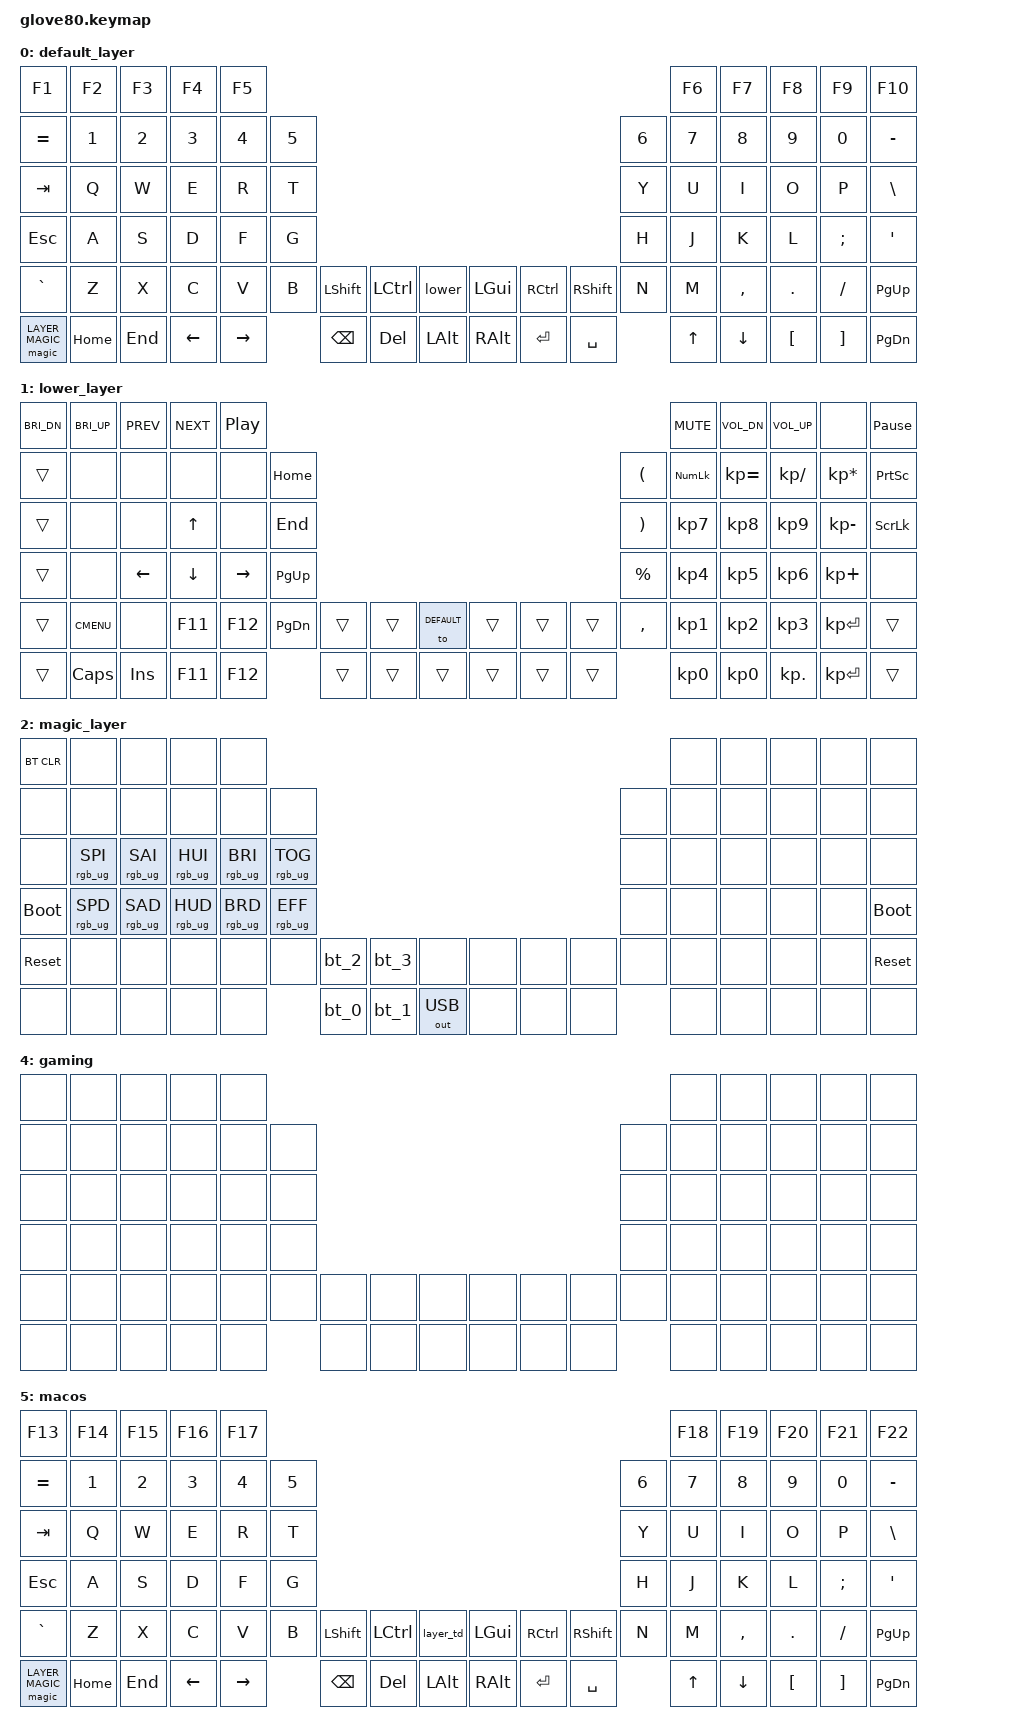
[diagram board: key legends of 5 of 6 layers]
/*
 * Copyright (c) 2020 The ZMK Contributors
 *
 * SPDX-License-Identifier: MIT
 */

#include <behaviors.dtsi>
#include <dt-bindings/zmk/keys.h>
#include <dt-bindings/zmk/bt.h>
#include <dt-bindings/zmk/ext_power.h>
#include <dt-bindings/zmk/outputs.h>
#include <dt-bindings/zmk/rgb.h>
#include "glove80_keypositions.h"

// layers

#define LAYER_DEFAULT      0
#define LAYER_LOWER        1
#define LAYER_MAGIC        2
#define LAYER_FUNCTION     3
#define LAYER_GAMING       4
#define LAYER_MACOS        5

/ {
    behaviors {
        // For the "layer" key, it'd nice to be able to use it as either a shift or a toggle.
        // Configure it as a tap dance, so the first tap (or hold) is a &mo and the second tap is a &to
        // layer_td: tap_dance_0 {
            // compatible = "zmk,behavior-tap-dance";
            // #binding-cells = <0>;
            // tapping-term-ms = <200>;
            // bindings = <&mo LOWER>, <&to LOWER>;
        // };
        vbatt: vbatt {
            compatible = "zmk,battery-nrf-vddh";
        };

        skq: sticky_key_quick_release {
            compatible = "zmk,behavior-sticky-key";
            #binding-cells = <1>;
            bindings = <&kp>;
            release-after-ms = <1000>;
            quick-release;
            ignore-modifiers;
        };

        lower: lower {
            compatible = "zmk,behavior-tap-dance";
            label = "LAYER_TAP_DANCE";
            #binding-cells = <0>;
            tapping-term-ms = <200>;
            bindings = <&mo LAYER_LOWER>, <&to LAYER_LOWER>;
        };

    };

    macros {
        rgb_ug_status_macro: rgb_ug_status_macro {
            label = "RGB_UG_STATUS";
            compatible = "zmk,behavior-macro";
            #binding-cells = <0>;
            bindings
                = <&rgb_ug RGB_STATUS>;
        };
    };
};

/ {
    behaviors {
        magic: magic {
            compatible = "zmk,behavior-hold-tap";
            label = "MAGIC_HOLD_TAP";
            #binding-cells = <1>;
            flavor = "tap-preferred";
            tapping-term-ms = <200>;
            bindings = <&mo>, <&rgb_ug_status_macro>;
        };
    }

};


/ {
#ifdef BT_DISC_CMD
    behaviors {
        bt_0: bt_0 {
            compatible = "zmk,behavior-tap-dance";
            label = "BT_0";
            #binding-cells = <0>;
            tapping-term-ms = <200>;
            bindings = <&bt_select_0>, <&bt BT_DISC 0>;
        };
        bt_1: bt_1 {
            compatible = "zmk,behavior-tap-dance";
            label = "BT_1";
            #binding-cells = <0>;
            tapping-term-ms = <200>;
            bindings = <&bt_select_1>, <&bt BT_DISC 1>;
        };
        bt_2: bt_2 {
            compatible = "zmk,behavior-tap-dance";
            label = "BT_2";
            #binding-cells = <0>;
            tapping-term-ms = <200>;
            bindings = <&bt_select_2>, <&bt BT_DISC 2>;
        };
        bt_3: bt_3 {
            compatible = "zmk,behavior-tap-dance";
            label = "BT_3";
            #binding-cells = <0>;
            tapping-term-ms = <200>;
            bindings = <&bt_select_3>, <&bt BT_DISC 3>;
        };
    };
    macros {
        bt_select_0: bt_select_0 {
            label = "BT_SELECT_0";
            compatible = "zmk,behavior-macro";
            #binding-cells = <0>;
            bindings
                = <&out OUT_BLE>,
                  <&bt BT_SEL 0>;
        };
        bt_select_1: bt_select_1 {
            label = "BT_SELECT_1";
            compatible = "zmk,behavior-macro";
            #binding-cells = <0>;
            bindings
                = <&out OUT_BLE>,
                  <&bt BT_SEL 1>;
        };
        bt_select_2: bt_select_2 {
            label = "BT_SELECT_2";
            compatible = "zmk,behavior-macro";
            #binding-cells = <0>;
            bindings
                = <&out OUT_BLE>,
                  <&bt BT_SEL 2>;
        };
        bt_select_3: bt_select_3 {
            label = "BT_SELECT_3";
            compatible = "zmk,behavior-macro";
            #binding-cells = <0>;
            bindings
                = <&out OUT_BLE>,
                  <&bt BT_SEL 3>;
        };
    };
#else
    macros {
        bt_0: bt_profile_macro_0 {
            compatible = "zmk,behavior-macro";
            #binding-cells = <0>;
            bindings
                = <&out OUT_BLE>,
                  <&bt BT_SEL 0>;
        };

        bt_1: bt_profile_macro_1 {
            compatible = "zmk,behavior-macro";
            #binding-cells = <0>;
            bindings
                = <&out OUT_BLE>,
                  <&bt BT_SEL 1>;
        };

        bt_2: bt_profile_macro_2 {
            compatible = "zmk,behavior-macro";
            #binding-cells = <0>;
            bindings
                = <&out OUT_BLE>,
                  <&bt BT_SEL 2>;
        };

        bt_3: bt_profile_macro_3 {
            compatible = "zmk,behavior-macro";
            #binding-cells = <0>;
            bindings
                = <&out OUT_BLE>,
                  <&bt BT_SEL 3>;
        };
    };
    #endif

    keymap {
        compatible = "zmk,keymap";

        default_layer {

            bindings = <
//    ┌──────────────────────┬──────┬─────┬──────┬──────┐                                                   ┌────┬──────┬────┬────┬──────┐
//    │          f1          │  f2  │ f3  │  f4  │  f5  │                                                   │ f6 │  f7  │ f8 │ f9 │ f10  │
//    ├──────────────────────┼──────┼─────┼──────┼──────┼───┐                                           ┌───┼────┼──────┼────┼────┼──────┤
//    │          =           │  1   │  2  │  3   │  4   │ 5 │                                           │ 6 │ 7  │  8   │ 9  │ 0  │  -   │
//    ├──────────────────────┼──────┼─────┼──────┼──────┼───┤                                           ├───┼────┼──────┼────┼────┼──────┤
//    │         tab          │  Q   │  W  │  E   │  R   │ T │                                           │ Y │ U  │  I   │ O  │ P  │  \   │
//    ├──────────────────────┼──────┼─────┼──────┼──────┼───┤                                           ├───┼────┼──────┼────┼────┼──────┤
//    │         esc          │  A   │  S  │  D   │  F   │ G │                                           │ H │ J  │  K   │ L  │ ;  │  '   │
//    ├──────────────────────┼──────┼─────┼──────┼──────┼───┼──────┬──────┬────────┬──────┬──────┬──────┼───┼────┼──────┼────┼────┼──────┤
//    │          `           │  Z   │  X  │  C   │  V   │ B │ lsft │ lctl │ &lower │ lgui │ rctl │ rsft │ N │ M  │  ,   │ .  │ /  │ pgup │
//    ├──────────────────────┼──────┼─────┼──────┼──────┼───┼──────┼──────┼────────┼──────┼──────┼──────┼───┼────┼──────┼────┼────┼──────┤
//    │ &magic laltYER_MAGIC │ home │ end │ left │ rght │   │ bspc │ del  │  lalt  │ ralt │ ent  │ spc  │   │ up │ down │ [  │ ]  │ pgdn │
//    └──────────────────────┴──────┴─────┴──────┴──────┘   └──────┴──────┴────────┴──────┴──────┴──────┘   └────┴──────┴────┴────┴──────┘
  &kp F1               &kp F2     &kp F3    &kp F4     &kp F5                                                                                              &kp F6   &kp F7      &kp F8     &kp F9     &kp F10
  &kp EQUAL            &kp N1     &kp N2    &kp N3     &kp N4      &kp N5                                                                         &kp N6   &kp N7   &kp N8      &kp N9     &kp N0     &kp MINUS
  &kp TAB              &kp Q      &kp W     &kp E      &kp R       &kp T                                                                          &kp Y    &kp U    &kp I       &kp O      &kp P      &kp BSLH
  &kp ESC              &kp A      &kp S     &kp D      &kp F       &kp G                                                                          &kp H    &kp J    &kp K       &kp L      &kp SEMI   &kp SQT
  &kp GRAVE            &kp Z      &kp X     &kp C      &kp V       &kp B    &kp LSHFT   &kp LCTRL   &lower     &kp LGUI   &kp RCTRL   &kp RSHFT   &kp N    &kp M    &kp COMMA   &kp DOT    &kp FSLH   &kp PG_UP
  &magic LAYER_MAGIC   &kp HOME   &kp END   &kp LEFT   &kp RIGHT            &kp BSPC    &kp DEL     &kp LALT   &kp RALT   &kp RET     &kp SPACE            &kp UP   &kp DOWN    &kp LBKT   &kp RBKT   &kp PG_DN
            >;
        };

        lower_layer {
            bindings = <
//    ┌──────┬──────┬──────┬──────┬──────┐                                                    ┌──────┬──────┬──────┬──────┬──────┐
//    │ bri- │ bri+ │ prev │ next │ play │                                                    │ mute │ vold │ volu │      │ paus │
//    ├──────┼──────┼──────┼──────┼──────┼──────┐                                         ┌───┼──────┼──────┼──────┼──────┼──────┤
//    │      │      │      │      │      │ home │                                         │ ( │ nlck │ kp_= │ kp_/ │ kp_* │ pscr │
//    ├──────┼──────┼──────┼──────┼──────┼──────┤                                         ├───┼──────┼──────┼──────┼──────┼──────┤
//    │      │      │      │  up  │      │ end  │                                         │ ) │  7   │  8   │  9   │ kp_- │ slck │
//    ├──────┼──────┼──────┼──────┼──────┼──────┤                                         ├───┼──────┼──────┼──────┼──────┼──────┤
//    │      │      │ left │ down │ rght │ pgup │                                         │ % │  4   │  5   │  6   │ kp_+ │      │
//    ├──────┼──────┼──────┼──────┼──────┼──────┼─────┬─────┬───────────┬─────┬─────┬─────┼───┼──────┼──────┼──────┼──────┼──────┤
//    │      │ app  │      │ f11  │ f12  │ pgdn │     │     │ to DEFAU< │     │     │     │ , │  1   │  2   │  3   │ ent  │      │
//    ├──────┼──────┼──────┼──────┼──────┼──────┼─────┼─────┼───────────┼─────┼─────┼─────┼───┼──────┼──────┼──────┼──────┼──────┤
//    │      │ caps │ ins  │ f11  │ f12  │      │     │     │           │     │     │     │   │  0   │  0   │ kp_. │ ent  │      │
//    └──────┴──────┴──────┴──────┴──────┘      └─────┴─────┴───────────┴─────┴─────┴─────┘   └──────┴──────┴──────┴──────┴──────┘
  &kp C_BRI_DN   &kp C_BRI_UP   &kp C_PREV   &kp C_NEXT   &kp C_PP                                                                                       &kp C_MUTE   &kp C_VOL_DN   &kp C_VOL_UP    &none             &kp PAUSE_BREAK
  &trans         &none          &none        &none        &none       &kp HOME                                                               &kp LPAR    &kp KP_NUM   &kp KP_EQUAL   &kp KP_DIVIDE   &kp KP_MULTIPLY   &kp PSCRN
  &trans         &none          &none        &kp UP       &none       &kp END                                                                &kp RPAR    &kp KP_N7    &kp KP_N8      &kp KP_N9       &kp KP_MINUS      &kp SLCK
  &trans         &none          &kp LEFT     &kp DOWN     &kp RIGHT   &kp PG_UP                                                              &kp PRCNT   &kp KP_N4    &kp KP_N5      &kp KP_N6       &kp KP_PLUS       &none
  &trans         &kp K_CMENU    &none        &kp F11      &kp F12     &kp PG_DN   &trans   &trans   &to DEFAULT   &trans   &trans   &trans   &kp COMMA   &kp KP_N1    &kp KP_N2      &kp KP_N3       &kp KP_ENTER      &trans
  &trans         &kp CAPS       &kp INS      &kp F11      &kp F12                 &trans   &trans   &trans        &trans   &trans   &trans               &kp KP_N0    &kp KP_N0      &kp KP_DOT      &kp KP_ENTER      &trans
            >;
        };

        magic_layer {
            bindings = <
//    ┌────────────┬─────────┬─────────┬─────────┬─────────┐                                                            ┌─────┬─────┬─────┬─────┬────────────┐
//    │   bt_clr   │         │         │         │         │                                                            │     │     │     │     │            │
//    ├────────────┼─────────┼─────────┼─────────┼─────────┼─────────┐                                            ┌─────┼─────┼─────┼─────┼─────┼────────────┤
//    │            │         │         │         │         │         │                                            │     │     │     │     │     │            │
//    ├────────────┼─────────┼─────────┼─────────┼─────────┼─────────┤                                            ├─────┼─────┼─────┼─────┼─────┼────────────┤
//    │            │ ug_ sp+ │ ug_ sa+ │ ug_ hu+ │ ug_ br+ │ ug_ tog │                                            │     │     │     │     │     │            │
//    ├────────────┼─────────┼─────────┼─────────┼─────────┼─────────┤                                            ├─────┼─────┼─────┼─────┼─────┼────────────┤
//    │    boot    │ ug_ sp- │ ug_ sa- │ ug_ hu- │ ug_ br- │ ug_ eff │                                            │     │     │     │     │     │    boot    │
//    ├────────────┼─────────┼─────────┼─────────┼─────────┼─────────┼───────┬───────┬──────────┬─────┬─────┬─────┼─────┼─────┼─────┼─────┼─────┼────────────┤
//    │ &sys_reset │         │         │         │         │         │ &bt_2 │ &bt_3 │          │     │     │     │     │     │     │     │     │ &sys_reset │
//    ├────────────┼─────────┼─────────┼─────────┼─────────┼─────────┼───────┼───────┼──────────┼─────┼─────┼─────┼─────┼─────┼─────┼─────┼─────┼────────────┤
//    │            │         │         │         │         │         │ &bt_0 │ &bt_1 │ out_ usb │     │     │     │     │     │     │     │     │            │
//    └────────────┴─────────┴─────────┴─────────┴─────────┘         └───────┴───────┴──────────┴─────┴─────┴─────┘     └─────┴─────┴─────┴─────┴────────────┘
  &bt BT_CLR    &none             &none             &none             &none                                                                                              &none   &none   &none   &none   &none
  &none         &none             &none             &none             &none             &none                                                                    &none   &none   &none   &none   &none   &none
  &none         &rgb_ug RGB_SPI   &rgb_ug RGB_SAI   &rgb_ug RGB_HUI   &rgb_ug RGB_BRI   &rgb_ug RGB_TOG                                                          &none   &none   &none   &none   &none   &none
  &bootloader   &rgb_ug RGB_SPD   &rgb_ug RGB_SAD   &rgb_ug RGB_HUD   &rgb_ug RGB_BRD   &rgb_ug RGB_EFF                                                          &none   &none   &none   &none   &none   &bootloader
  &sys_reset    &none             &none             &none             &none             &none             &bt_2   &bt_3   &none          &none   &none   &none   &none   &none   &none   &none   &none   &sys_reset
  &none         &none             &none             &none             &none                               &bt_0   &bt_1   &out OUT_USB   &none   &none   &none           &none   &none   &none   &none   &none
            >;
        };
      function {
        bindings = <
//    ┌─────┬─────────┬─────────┬─────────┬─────────┐                                                       ┌─────┬─────┬─────┬─────┬─────┐
//    │     │         │         │         │         │                                                       │     │     │     │     │     │
//    ├─────┼─────────┼─────────┼─────────┼─────────┼─────────┐                                       ┌─────┼─────┼─────┼─────┼─────┼─────┤
//    │     │         │         │         │         │         │                                       │     │     │     │     │     │     │
//    ├─────┼─────────┼─────────┼─────────┼─────────┼─────────┤                                       ├─────┼─────┼─────┼─────┼─────┼─────┤
//    │     │     sp+ │     sa+ │     hu+ │     br+ │     tog │                                       │     │     │     │     │     │     │
//    ├─────┼─────────┼─────────┼─────────┼─────────┼─────────┤                                       ├─────┼─────┼─────┼─────┼─────┼─────┤
//    │     │     sp- │     sa- │     hu- │     br- │     eff │                                       │     │     │     │     │     │     │
//    ├─────┼─────────┼─────────┼─────────┼─────────┼─────────┼─────┬─────┬─────────┬─────┬─────┬─────┼─────┼─────┼─────┼─────┼─────┼─────┤
//    │     │         │         │         │         │         │     │     │         │     │     │     │     │     │     │     │     │     │
//    ├─────┼─────────┼─────────┼─────────┼─────────┼─────────┼─────┼─────┼─────────┼─────┼─────┼─────┼─────┼─────┼─────┼─────┼─────┼─────┤
//    │     │         │         │         │         │         │     │     │     usb │     │     │     │     │     │     │     │     │     │
//    └─────┴─────────┴─────────┴─────────┴─────────┘         └─────┴─────┴─────────┴─────┴─────┴─────┘     └─────┴─────┴─────┴─────┴─────┘
  &trans   &trans           &trans           &trans           &trans                                                                                                   &trans   &trans   &trans   &trans   &trans
  &trans   &trans           &trans           &trans           &trans           &trans                                                                         &trans   &trans   &trans   &trans   &trans   &trans
  &trans   &trans RGB_SPI   &trans RGB_SAI   &trans RGB_HUI   &trans RGB_BRI   &trans RGB_TOG                                                                 &trans   &trans   &trans   &trans   &trans   &trans
  &trans   &trans RGB_SPD   &trans RGB_SAD   &trans RGB_HUD   &trans RGB_BRD   &trans RGB_EFF                                                                 &trans   &trans   &trans   &trans   &trans   &trans
  &trans   &trans           &trans           &trans           &trans           &trans           &trans   &trans   &trans           &trans   &trans   &trans   &trans   &trans   &trans   &trans   &trans   &trans
  &trans   &trans           &trans           &trans           &trans                            &trans   &trans   &trans OUT_USB   &trans   &trans   &trans            &trans   &trans   &trans   &trans   &trans
            >;
        };
      gaming {
        bindings = <
//    ┌─────┬─────┬─────┬─────┬─────┐                                               ┌─────┬─────┬─────┬─────┬─────┐
//    │     │     │     │     │     │                                               │     │     │     │     │     │
//    ├─────┼─────┼─────┼─────┼─────┼─────┐                                   ┌─────┼─────┼─────┼─────┼─────┼─────┤
//    │     │     │     │     │     │     │                                   │     │     │     │     │     │     │
//    ├─────┼─────┼─────┼─────┼─────┼─────┤                                   ├─────┼─────┼─────┼─────┼─────┼─────┤
//    │     │     │     │     │     │     │                                   │     │     │     │     │     │     │
//    ├─────┼─────┼─────┼─────┼─────┼─────┤                                   ├─────┼─────┼─────┼─────┼─────┼─────┤
//    │     │     │     │     │     │     │                                   │     │     │     │     │     │     │
//    ├─────┼─────┼─────┼─────┼─────┼─────┼─────┬─────┬─────┬─────┬─────┬─────┼─────┼─────┼─────┼─────┼─────┼─────┤
//    │     │     │     │     │     │     │     │     │     │     │     │     │     │     │     │     │     │     │
//    ├─────┼─────┼─────┼─────┼─────┼─────┼─────┼─────┼─────┼─────┼─────┼─────┼─────┼─────┼─────┼─────┼─────┼─────┤
//    │     │     │     │     │     │     │     │     │     │     │     │     │     │     │     │     │     │     │
//    └─────┴─────┴─────┴─────┴─────┘     └─────┴─────┴─────┴─────┴─────┴─────┘     └─────┴─────┴─────┴─────┴─────┘
  &none   &none   &none   &none   &none                                                                   &none   &none   &none   &none   &none
  &none   &none   &none   &none   &none   &none                                                   &none   &none   &none   &none   &none   &none
  &none   &none   &none   &none   &none   &none                                                   &none   &none   &none   &none   &none   &none
  &none   &none   &none   &none   &none   &none                                                   &none   &none   &none   &none   &none   &none
  &none   &none   &none   &none   &none   &none   &none   &none   &none   &none   &none   &none   &none   &none   &none   &none   &none   &none
  &none   &none   &none   &none   &none           &none   &none   &none   &none   &none   &none           &none   &none   &none   &none   &none
            >;
        };

      macos {
        bindings = <
//    ┌────────────────────────┬──────┬─────┬──────┬──────┐                                                      ┌─────┬──────┬─────┬─────┬──────┐
//    │          f13           │ f14  │ f15 │ f16  │ f17  │                                                      │ f18 │ f19  │ f20 │ f21 │ f22  │
//    ├────────────────────────┼──────┼─────┼──────┼──────┼───┐                                              ┌───┼─────┼──────┼─────┼─────┼──────┤
//    │           =            │  1   │  2  │  3   │  4   │ 5 │                                              │ 6 │  7  │  8   │  9  │  0  │  -   │
//    ├────────────────────────┼──────┼─────┼──────┼──────┼───┤                                              ├───┼─────┼──────┼─────┼─────┼──────┤
//    │          tab           │  Q   │  W  │  E   │  R   │ T │                                              │ Y │  U  │  I   │  O  │  P  │  \   │
//    ├────────────────────────┼──────┼─────┼──────┼──────┼───┤                                              ├───┼─────┼──────┼─────┼─────┼──────┤
//    │          esc           │  A   │  S  │  D   │  F   │ G │                                              │ H │  J  │  K   │  L  │  ;  │  '   │
//    ├────────────────────────┼──────┼─────┼──────┼──────┼───┼──────┬──────┬───────────┬──────┬──────┬──────┼───┼─────┼──────┼─────┼─────┼──────┤
//    │           `            │  Z   │  X  │  C   │  V   │ B │ lsft │ lctl │ &layer_td │ lgui │ rctl │ rsft │ N │  M  │  ,   │  .  │  /  │ pgup │
//    ├────────────────────────┼──────┼─────┼──────┼──────┼───┼──────┼──────┼───────────┼──────┼──────┼──────┼───┼─────┼──────┼─────┼─────┼──────┤
//    │ &magic laltYER_MAGIC 0 │ home │ end │ left │ rght │   │ bspc │ del  │   lalt    │ ralt │ ent  │ spc  │   │ up  │ down │  [  │  ]  │ pgdn │
//    └────────────────────────┴──────┴─────┴──────┴──────┘   └──────┴──────┴───────────┴──────┴──────┴──────┘   └─────┴──────┴─────┴─────┴──────┘
  &kp F13                &kp F14    &kp F15   &kp F16    &kp F17                                                                                              &kp F18   &kp F19     &kp F20    &kp F21    &kp F22
  &kp EQUAL              &kp N1     &kp N2    &kp N3     &kp N4      &kp N5                                                                          &kp N6   &kp N7    &kp N8      &kp N9     &kp N0     &kp MINUS
  &kp TAB                &kp Q      &kp W     &kp E      &kp R       &kp T                                                                           &kp Y    &kp U     &kp I       &kp O      &kp P      &kp BSLH
  &kp ESC                &kp A      &kp S     &kp D      &kp F       &kp G                                                                           &kp H    &kp J     &kp K       &kp L      &kp SEMI   &kp SQT
  &kp GRAVE              &kp Z      &kp X     &kp C      &kp V       &kp B    &kp LSHFT   &kp LCTRL   &layer_td   &kp LGUI   &kp RCTRL   &kp RSHFT   &kp N    &kp M     &kp COMMA   &kp DOT    &kp FSLH   &kp PG_UP
  &magic LAYER_MAGIC 0   &kp HOME   &kp END   &kp LEFT   &kp RIGHT            &kp BSPC    &kp DEL     &kp LALT    &kp RALT   &kp RET     &kp SPACE            &kp UP    &kp DOWN    &kp LBKT   &kp RBKT   &kp PG_DN
            >;
        };
    };
};
